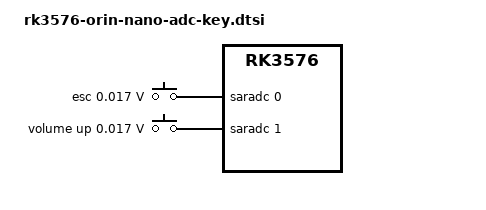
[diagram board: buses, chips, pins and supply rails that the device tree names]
// SPDX-License-Identifier: (GPL-2.0+ OR MIT)
/*
 * Guangzhou Easy EAI Technology Co., Ltd.
 *
 */
#include "rk3576-evb-input-keymap.dtsi"

/ {
	adc_keys0: adc-keys0 {
		compatible = "adc-keys";
		io-channels = <&saradc 0>;
		io-channel-names = "buttons";
		keyup-threshold-microvolt = <1800000>;
		poll-interval = <100>;

		vol-up-key {
			label = "esc";
			linux,code = <KEY_ESC>;
			press-threshold-microvolt = <17000>;
		};
	};

	adc_keys: adc-keys {
		compatible = "adc-keys";
		io-channels = <&saradc 1>;
		io-channel-names = "buttons";
		keyup-threshold-microvolt = <1800000>;
		poll-interval = <100>;

		vol-up-key {
			label = "volume up";
			linux,code = <KEY_VOLUMEUP>;
			press-threshold-microvolt = <17000>;
		};
	};
}
